AUTOSAR XML (schema 00046)
package /ComponentTypes
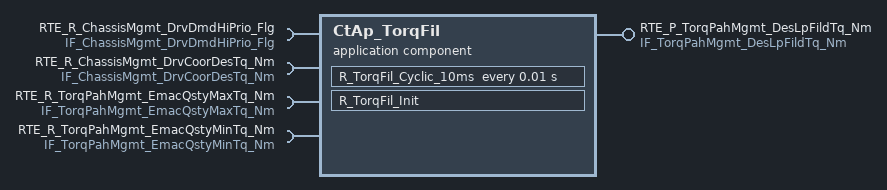
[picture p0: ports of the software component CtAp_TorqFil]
  application sw component type CtAp_TorqFil
    4 x require port:
      RTE_R_ChassisMgmt_DrvDmdHiPrio_Flg: nonqueued-receiver-com-spec{data-element=tec_ChassisMgmt_DrvDmdHiPrio_Flg, filter=data-filter-type=ALWAYS, init-value=0}, required-interface=IF_ChassisMgmt_DrvDmdHiPrio_Flg
      RTE_R_ChassisMgmt_DrvCoorDesTq_Nm: nonqueued-receiver-com-spec{data-element=tec_ChassisMgmt_DrvCoorDesTq_Nm, filter=data-filter-type=ALWAYS, init-value=0}, required-interface=IF_ChassisMgmt_DrvCoorDesTq_Nm
      RTE_R_TorqPahMgmt_EmacQstyMaxTq_Nm: nonqueued-receiver-com-spec{data-element=tec_TorqPahMgmt_EmacQstyMaxTq_Nm, filter=data-filter-type=ALWAYS, init-value=0}, required-interface=IF_TorqPahMgmt_EmacQstyMaxTq_Nm
      RTE_R_TorqPahMgmt_EmacQstyMinTq_Nm: nonqueued-receiver-com-spec{data-element=tec_TorqPahMgmt_EmacQstyMinTq_Nm, filter=data-filter-type=ALWAYS, init-value=0}, required-interface=IF_TorqPahMgmt_EmacQstyMinTq_Nm
    provide port RTE_P_TorqPahMgmt_DesLpFildTq_Nm: nonqueued-sender-com-spec{data-element=tec_TorqPahMgmt_DesLpFildTq_Nm, init-value=0}, provided-interface=IF_TorqPahMgmt_DesLpFildTq_Nm
    behavior CtAp_TorqFil_InternalBehavior
      init event CtAp_TorqFil_InitEvent: start-on-event=R_TorqFil_Init
      timing event TMT_R_TorqFil_Cyclic_10ms: start-on-event=R_TorqFil_Cyclic_10ms, period=0.01
      runnable R_TorqFil_Init
      runnable R_TorqFil_Cyclic_10ms
        data-receive-point-by-arguments:
          4 x access:
            REC_RTE_R_ChassisMgmt_DrvCoorDesTq_Nm_tec_ChassisMgmt_DrvCoorDesTq_Nm: accessed-variable=RTE_R_ChassisMgmt_DrvCoorDesTq_Nm.tec_ChassisMgmt_DrvCoorDesTq_Nm
            REC_RTE_R_ChassisMgmt_DrvDmdHiPrio_Flg_tec_ChassisMgmt_DrvDmdHiPrio_Flg: accessed-variable=RTE_R_ChassisMgmt_DrvDmdHiPrio_Flg.tec_ChassisMgmt_DrvDmdHiPrio_Flg
            REC_RTE_R_TorqPahMgmt_EmacQstyMaxTq_Nm_tec_TorqPahMgmt_EmacQstyMaxTq_Nm: accessed-variable=RTE_R_TorqPahMgmt_EmacQstyMaxTq_Nm.tec_TorqPahMgmt_EmacQstyMaxTq_Nm
            REC_RTE_R_TorqPahMgmt_EmacQstyMinTq_Nm_tec_TorqPahMgmt_EmacQstyMinTq_Nm: accessed-variable=RTE_R_TorqPahMgmt_EmacQstyMinTq_Nm.tec_TorqPahMgmt_EmacQstyMinTq_Nm
        data-send-points:
          access SEND_RTE_P_TorqPahMgmt_DesLpFildTq_Nm_tec_TorqPahMgmt_DesLpFildTq_Nm: accessed-variable=RTE_P_TorqPahMgmt_DesLpFildTq_Nm.tec_TorqPahMgmt_DesLpFildTq_Nm
  swc implementation CtAp_TorqFil_Implementation: behavior=CtAp_TorqFil_InternalBehavior
    code-descriptors:
      code Default: artifact-descriptors=autosar-engineering-object=category=SWOBJ
